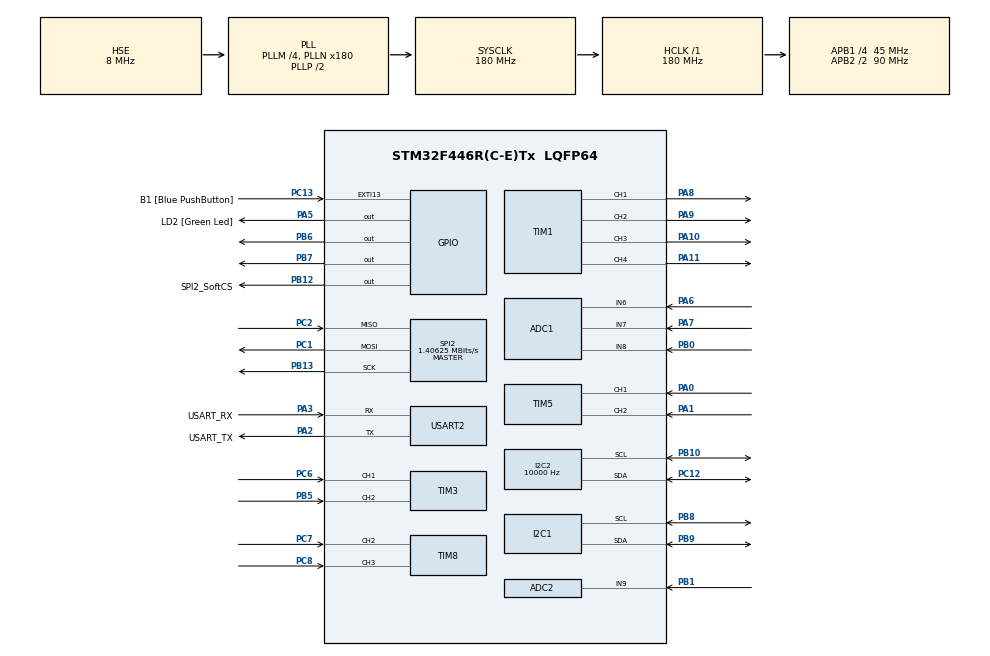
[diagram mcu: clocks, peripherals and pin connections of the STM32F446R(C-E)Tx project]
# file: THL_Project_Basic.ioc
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ADC1.Channel-0\#ChannelRegularConversion=ADC_CHANNEL_6
ADC1.Channel-1\#ChannelRegularConversion=ADC_CHANNEL_7
ADC1.Channel-2\#ChannelRegularConversion=ADC_CHANNEL_8
ADC1.Channel-3\#ChannelRegularConversion=ADC_CHANNEL_TEMPSENSOR
ADC1.ContinuousConvMode=ENABLE
ADC1.DMAContinuousRequests=ENABLE
ADC1.ExternalTrigConv=ADC_SOFTWARE_START
ADC1.InjNumberOfConversion=0
ADC1.NbrOfConversion=4
ADC1.NbrOfConversionFlag=1
ADC1.Rank-0\#ChannelRegularConversion=1
ADC1.Rank-1\#ChannelRegularConversion=2
ADC1.Rank-2\#ChannelRegularConversion=3
ADC1.Rank-3\#ChannelRegularConversion=4
ADC1.SamplingTime-0\#ChannelRegularConversion=ADC_SAMPLETIME_56CYCLES
ADC1.SamplingTime-1\#ChannelRegularConversion=ADC_SAMPLETIME_56CYCLES
ADC1.SamplingTime-2\#ChannelRegularConversion=ADC_SAMPLETIME_56CYCLES
ADC1.SamplingTime-3\#ChannelRegularConversion=ADC_SAMPLETIME_480CYCLES
ADC1.ScanConvMode=ENABLE
ADC1.master=1
ADC2.Channel-15\#ChannelRegularConversion=ADC_CHANNEL_9
ADC2.ContinuousConvMode=DISABLE
ADC2.NbrOfConversion=1
ADC2.NbrOfConversionFlag=1
ADC2.Rank-15\#ChannelRegularConversion=1
ADC2.SamplingTime-15\#ChannelRegularConversion=ADC_SAMPLETIME_480CYCLES
Dma.ADC1.4.Direction=DMA_PERIPH_TO_MEMORY
Dma.ADC1.4.FIFOMode=DMA_FIFOMODE_DISABLE
Dma.ADC1.4.Instance=DMA2_Stream0
Dma.ADC1.4.MemDataAlignment=DMA_MDATAALIGN_HALFWORD
Dma.ADC1.4.MemInc=DMA_MINC_ENABLE
Dma.ADC1.4.Mode=DMA_CIRCULAR
Dma.ADC1.4.PeriphDataAlignment=DMA_PDATAALIGN_HALFWORD
Dma.ADC1.4.PeriphInc=DMA_PINC_DISABLE
Dma.ADC1.4.Priority=DMA_PRIORITY_LOW
Dma.I2C1_RX.1.Direction=DMA_PERIPH_TO_MEMORY
Dma.I2C1_RX.1.FIFOMode=DMA_FIFOMODE_DISABLE
Dma.I2C1_RX.1.Instance=DMA1_Stream0
Dma.I2C1_RX.1.MemDataAlignment=DMA_MDATAALIGN_BYTE
Dma.I2C1_RX.1.MemInc=DMA_MINC_ENABLE
Dma.I2C1_RX.1.Mode=DMA_NORMAL
Dma.I2C1_RX.1.PeriphDataAlignment=DMA_PDATAALIGN_BYTE
Dma.I2C1_RX.1.PeriphInc=DMA_PINC_DISABLE
Dma.I2C1_RX.1.Priority=DMA_PRIORITY_VERY_HIGH
Dma.I2C1_TX.0.Direction=DMA_MEMORY_TO_PERIPH
Dma.I2C1_TX.0.FIFOMode=DMA_FIFOMODE_DISABLE
Dma.I2C1_TX.0.Instance=DMA1_Stream7
Dma.I2C1_TX.0.MemDataAlignment=DMA_MDATAALIGN_BYTE
Dma.I2C1_TX.0.MemInc=DMA_MINC_ENABLE
Dma.I2C1_TX.0.Mode=DMA_NORMAL
Dma.I2C1_TX.0.PeriphDataAlignment=DMA_PDATAALIGN_BYTE
Dma.I2C1_TX.0.PeriphInc=DMA_PINC_DISABLE
Dma.I2C1_TX.0.Priority=DMA_PRIORITY_VERY_HIGH
Dma.Request0=I2C1_TX
Dma.Request1=I2C1_RX
Dma.Request2=SPI2_RX
Dma.Request3=SPI2_TX
Dma.Request4=ADC1
Dma.SPI2_RX.2.Direction=DMA_PERIPH_TO_MEMORY
Dma.SPI2_RX.2.FIFOMode=DMA_FIFOMODE_DISABLE
Dma.SPI2_RX.2.Instance=DMA1_Stream3
Dma.SPI2_RX.2.MemDataAlignment=DMA_MDATAALIGN_BYTE
Dma.SPI2_RX.2.MemInc=DMA_MINC_ENABLE
Dma.SPI2_RX.2.Mode=DMA_NORMAL
Dma.SPI2_RX.2.PeriphDataAlignment=DMA_PDATAALIGN_BYTE
Dma.SPI2_RX.2.PeriphInc=DMA_PINC_DISABLE
Dma.SPI2_RX.2.Priority=DMA_PRIORITY_LOW
Dma.SPI2_TX.3.Direction=DMA_MEMORY_TO_PERIPH
Dma.SPI2_TX.3.FIFOMode=DMA_FIFOMODE_DISABLE
Dma.SPI2_TX.3.Instance=DMA1_Stream4
Dma.SPI2_TX.3.MemDataAlignment=DMA_MDATAALIGN_BYTE
Dma.SPI2_TX.3.MemInc=DMA_MINC_ENABLE
Dma.SPI2_TX.3.Mode=DMA_NORMAL
Dma.SPI2_TX.3.PeriphDataAlignment=DMA_PDATAALIGN_BYTE
Dma.SPI2_TX.3.PeriphInc=DMA_PINC_DISABLE
Dma.SPI2_TX.3.Priority=DMA_PRIORITY_LOW
I2C1.OwnAddress=6
I2C2.ClockSpeed=10000
I2C2.OwnAddress=3
Mcu.Family=STM32F4
Mcu.Name=STM32F446R(C-E)Tx
Mcu.Package=LQFP64
NVIC.ADC_IRQn=true\:0\:0\:false\:false\:true\:true
NVIC.DMA1_Stream0_IRQn=true\:0\:0\:false\:false\:true\:false
NVIC.DMA1_Stream3_IRQn=true\:0\:0\:false\:false\:true\:false
NVIC.DMA1_Stream4_IRQn=true\:0\:0\:false\:false\:true\:false
NVIC.DMA1_Stream7_IRQn=true\:0\:0\:false\:false\:true\:false
NVIC.DMA2_Stream0_IRQn=true\:0\:0\:false\:false\:true\:false
NVIC.I2C1_ER_IRQn=true\:0\:0\:false\:false\:true\:true
NVIC.I2C1_EV_IRQn=true\:0\:0\:false\:false\:true\:true
NVIC.PriorityGroup=NVIC_PRIORITYGROUP_4
NVIC.SPI2_IRQn=true\:0\:0\:false\:false\:true\:true
NVIC.TIM1_UP_TIM10_IRQn=true\:0\:0\:false\:false\:true\:true
NVIC.TIM3_IRQn=true\:0\:0\:false\:false\:true\:true
NVIC.TIM5_IRQn=true\:0\:0\:false\:false\:true\:true
NVIC.TIM7_IRQn=true\:0\:0\:false\:false\:true\:true
NVIC.TIM8_CC_IRQn=true\:0\:0\:false\:false\:true\:true
NVIC.TIM8_UP_TIM13_IRQn=true\:0\:0\:false\:false\:true\:true
PA0-WKUP.Signal=S_TIM5_CH1
PA1.Signal=S_TIM5_CH2
PA10.Signal=S_TIM1_CH3
PA11.Signal=S_TIM1_CH4
PA13.GPIO_Label=TMS
PA13.Mode=Serial_Wire
PA13.Signal=SYS_JTMS-SWDIO
PA14.GPIO_Label=TCK
PA14.Mode=Serial_Wire
PA14.Signal=SYS_JTCK-SWCLK
PA2.GPIO_Label=USART_TX
PA2.Mode=Asynchronous
PA2.Signal=USART2_TX
PA3.GPIO_Label=USART_RX
PA3.Mode=Asynchronous
PA3.Signal=USART2_RX
PA5.GPIO_Label=LD2 [Green Led]
PA5.Signal=GPIO_Output
PA6.Signal=ADCx_IN6
PA7.Signal=ADCx_IN7
PA8.Signal=S_TIM1_CH1
PA9.Signal=S_TIM1_CH2
PB0.Signal=ADCx_IN8
PB1.Signal=ADCx_IN9
PB10.GPIO_PuPdOD=GPIO_PULLUP
PB10.Mode=I2C
PB10.Signal=I2C2_SCL
PB12.GPIO_Label=SPI2_SoftCS
PB12.Signal=GPIO_Output
PB13.Mode=Full_Duplex_Master
PB13.Signal=SPI2_SCK
PB3.GPIO_Label=SWO
PB3.Signal=SYS_JTDO-SWO
PB5.Signal=S_TIM3_CH2
PB6.GPIO_Speed=GPIO_SPEED_FREQ_VERY_HIGH
PB6.Signal=GPIO_Output
PB7.GPIO_Speed=GPIO_SPEED_FREQ_VERY_HIGH
PB7.Signal=GPIO_Output
PB8.GPIO_Mode=GPIO_MODE_AF_OD
PB8.GPIO_PuPdOD=GPIO_NOPULL
PB8.Mode=I2C
PB8.Signal=I2C1_SCL
PB9.GPIO_PuPdOD=GPIO_NOPULL
PB9.Mode=I2C
PB9.Signal=I2C1_SDA
PC1.Mode=Full_Duplex_Master
PC1.Signal=SPI2_MOSI
PC12.Mode=I2C
PC12.Signal=I2C2_SDA
PC13.GPIO_Label=B1 [Blue PushButton]
PC13.GPIO_ModeDefaultEXTI=GPIO_MODE_IT_FALLING
PC13.Signal=GPXTI13
PC14-OSC32_IN.Mode=LSE-External-Oscillator
PC14-OSC32_IN.Signal=RCC_OSC32_IN
PC15-OSC32_OUT.Mode=LSE-External-Oscillator
PC15-OSC32_OUT.Signal=RCC_OSC32_OUT
PC2.Mode=Full_Duplex_Master
PC2.Signal=SPI2_MISO
PC6.Signal=S_TIM3_CH1
PC7.Signal=S_TIM8_CH2
PC8.Signal=S_TIM8_CH3
PH0-OSC_IN.Mode=HSE-External-Oscillator
PH0-OSC_IN.Signal=RCC_OSC_IN
PH1-OSC_OUT.Mode=HSE-External-Oscillator
PH1-OSC_OUT.Signal=RCC_OSC_OUT
ProjectManager.HeapSize=0x200
ProjectManager.StackSize=0x400
ProjectManager.TargetToolchain=TrueSTUDIO
RCC.48MHZClocksFreq_Value=84000000
RCC.AHBFreq_Value=180000000
RCC.APB1CLKDivider=RCC_HCLK_DIV4
RCC.APB1Freq_Value=45000000
RCC.APB1TimFreq_Value=90000000
RCC.APB2CLKDivider=RCC_HCLK_DIV2
RCC.APB2Freq_Value=90000000
RCC.APB2TimFreq_Value=180000000
RCC.CortexFreq_Value=180000000
RCC.FLatency-AdvancedSettings=FLASH_LATENCY_5
RCC.HCLKFreq_Value=180000000
RCC.HSE_VALUE=8000000
RCC.HSI_VALUE=16000000
RCC.PLLM=4
RCC.PLLN=180
RCC.PLLSourceVirtual=RCC_PLLSOURCE_HSE
RCC.SYSCLKFreq_VALUE=180000000
RCC.SYSCLKSource=RCC_SYSCLKSOURCE_PLLCLK
RCC.USBFreq_Value=180000000
RCC.VCOOutputFreq_Value=360000000
SH.ADCx_IN6.0=ADC1_IN6,IN6
SH.ADCx_IN7.0=ADC1_IN7,IN7
SH.ADCx_IN8.0=ADC1_IN8,IN8
SH.ADCx_IN9.0=ADC2_IN9,IN9
SH.S_TIM1_CH1.0=TIM1_CH1,PWM Generation1 CH1
SH.S_TIM1_CH2.0=TIM1_CH2,PWM Generation2 CH2
SH.S_TIM1_CH3.0=TIM1_CH3,PWM Generation3 CH3
SH.S_TIM1_CH4.0=TIM1_CH4,PWM Generation4 CH4
SH.S_TIM3_CH1.0=TIM3_CH1,Encoder_Interface
SH.S_TIM3_CH2.0=TIM3_CH2,Encoder_Interface
SH.S_TIM5_CH1.0=TIM5_CH1,Encoder_Interface
SH.S_TIM5_CH2.0=TIM5_CH2,Encoder_Interface
SH.S_TIM8_CH2.0=TIM8_CH2,Input_Capture2_from_TI2
SH.S_TIM8_CH3.0=TIM8_CH3,Input_Capture3_from_TI3
SPI2.BaudRatePrescaler=SPI_BAUDRATEPRESCALER_32
SPI2.CLKPhase=SPI_PHASE_2EDGE
SPI2.CLKPolarity=SPI_POLARITY_HIGH
SPI2.CalculateBaudRate=1.40625 MBits/s
SPI2.Direction=SPI_DIRECTION_2LINES
SPI2.Mode=SPI_MODE_MASTER
SPI2.TIMode=SPI_TIMODE_DISABLE
SPI2.VirtualType=VM_MASTER
TIM1.Channel-PWM\ Generation1\ CH1=TIM_CHANNEL_1
TIM1.Channel-PWM\ Generation2\ CH2=TIM_CHANNEL_2
TIM1.Channel-PWM\ Generation3\ CH3=TIM_CHANNEL_3
TIM1.Channel-PWM\ Generation4\ CH4=TIM_CHANNEL_4
TIM8.Channel-Input_Capture2_from_TI2=TIM_CHANNEL_2
TIM8.Channel-Input_Capture3_from_TI3=TIM_CHANNEL_3
USART2.VirtualMode=VM_ASYNC
VP_ADC1_TempSens_Input.Mode=IN-TempSens
VP_TIM10_VS_ClockSourceINT.Mode=Enable_Timer
VP_TIM7_VS_ClockSourceINT.Mode=Enable_Timer
board=NUCLEO-F446RE

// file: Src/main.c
/* USER CODE BEGIN Header */
/**
  ******************************************************************************
  * @file           : main.c
  * @brief          : Main program body
  ******************************************************************************
  ** This notice applies to any and all portions of this file
  * that are not between comment pairs USER CODE BEGIN and
  * USER CODE END. Other portions of this file, whether
  * inserted by the user or by software development tools
  * are owned by their respective copyright owners.
  *
  * COPYRIGHT(c) 2018 STMicroelectronics
  *
  * Redistribution and use in source and binary forms, with or without modification,
  * are permitted provided that the following conditions are met:
  *   1. Redistributions of source code must retain the above copyright notice,
  *      this list of conditions and the following disclaimer.
  *   2. Redistributions in binary form must reproduce the above copyright notice,
  *      this list of conditions and the following disclaimer in the documentation
  *      and/or other materials provided with the distribution.
  *   3. Neither the name of STMicroelectronics nor the names of its contributors
  *      may be used to endorse or promote products derived from this software
  *      without specific prior written permission.
  *
  * THIS SOFTWARE IS PROVIDED BY THE COPYRIGHT HOLDERS AND CONTRIBUTORS "AS IS"
  * AND ANY EXPRESS OR IMPLIED WARRANTIES, INCLUDING, BUT NOT LIMITED TO, THE
  * IMPLIED WARRANTIES OF MERCHANTABILITY AND FITNESS FOR A PARTICULAR PURPOSE ARE
  * DISCLAIMED. IN NO EVENT SHALL THE COPYRIGHT HOLDER OR CONTRIBUTORS BE LIABLE
  * FOR ANY DIRECT, INDIRECT, INCIDENTAL, SPECIAL, EXEMPLARY, OR CONSEQUENTIAL
  * DAMAGES (INCLUDING, BUT NOT LIMITED TO, PROCUREMENT OF SUBSTITUTE GOODS OR
  * SERVICES; LOSS OF USE, DATA, OR PROFITS; OR BUSINESS INTERRUPTION) HOWEVER
  * CAUSED AND ON ANY THEORY OF LIABILITY, WHETHER IN CONTRACT, STRICT LIABILITY,
  * OR TORT (INCLUDING NEGLIGENCE OR OTHERWISE) ARISING IN ANY WAY OUT OF THE USE
  * OF THIS SOFTWARE, EVEN IF ADVISED OF THE POSSIBILITY OF SUCH DAMAGE.
  *
  ******************************************************************************
  */
/* USER CODE END Header */

#include "main.h"

/* USER CODE BEGIN Includes */
#include "Prj_Main.h"
/* USER CODE END Includes */

ADC_HandleTypeDef hadc1;
ADC_HandleTypeDef hadc2;
DMA_HandleTypeDef hdma_adc1;

I2C_HandleTypeDef hi2c1;
I2C_HandleTypeDef hi2c2;
DMA_HandleTypeDef hdma_i2c1_tx;
DMA_HandleTypeDef hdma_i2c1_rx;

SPI_HandleTypeDef hspi2;
DMA_HandleTypeDef hdma_spi2_rx;
DMA_HandleTypeDef hdma_spi2_tx;

TIM_HandleTypeDef htim1;
TIM_HandleTypeDef htim3;
TIM_HandleTypeDef htim5;
TIM_HandleTypeDef htim7;
TIM_HandleTypeDef htim8;
TIM_HandleTypeDef htim10;

UART_HandleTypeDef huart2;

void SystemClock_Config(void);
static void MX_GPIO_Init(void);
static void MX_DMA_Init(void);
static void MX_USART2_UART_Init(void);
static void MX_TIM1_Init(void);
static void MX_I2C1_Init(void);
static void MX_I2C2_Init(void);
static void MX_SPI2_Init(void);
static void MX_ADC1_Init(void);
static void MX_TIM8_Init(void);
static void MX_TIM7_Init(void);
static void MX_TIM5_Init(void);
static void MX_TIM3_Init(void);
static void MX_TIM10_Init(void);
static void MX_ADC2_Init(void);

int main(void)
{

  /* MCU Configuration--------------------------------------------------------*/

  /* Reset of all peripherals, Initializes the Flash interface and the Systick. */
  HAL_Init();

  /* Configure the system clock */
  SystemClock_Config();

  /* Initialize all configured peripherals */
  MX_GPIO_Init();
  MX_DMA_Init();
  MX_USART2_UART_Init();
  MX_TIM1_Init();
  MX_I2C1_Init();
  MX_I2C2_Init();
  MX_SPI2_Init();
  MX_ADC1_Init();
  MX_TIM8_Init();
  MX_TIM7_Init();
  MX_TIM5_Init();
  MX_TIM3_Init();
  MX_TIM10_Init();
  MX_ADC2_Init();
  /* USER CODE BEGIN 2 */
  prj_main();
  /* USER CODE END 2 */

  /* Infinite loop */
  while (1)
  {

  }
}

void SystemClock_Config(void)
{
  RCC_OscInitTypeDef RCC_OscInitStruct = {0};
  RCC_ClkInitTypeDef RCC_ClkInitStruct = {0};

  /**Configure the main internal regulator output voltage
  */
  __HAL_RCC_PWR_CLK_ENABLE();
  __HAL_PWR_VOLTAGESCALING_CONFIG(PWR_REGULATOR_VOLTAGE_SCALE1);
  /**Initializes the CPU, AHB and APB busses clocks
  */
  RCC_OscInitStruct.OscillatorType = RCC_OSCILLATORTYPE_HSE;
  RCC_OscInitStruct.HSEState = RCC_HSE_ON;
  RCC_OscInitStruct.PLL.PLLState = RCC_PLL_ON;
  RCC_OscInitStruct.PLL.PLLSource = RCC_PLLSOURCE_HSE;
  RCC_OscInitStruct.PLL.PLLM = 4;
  RCC_OscInitStruct.PLL.PLLN = 180;
  RCC_OscInitStruct.PLL.PLLP = RCC_PLLP_DIV2;
  RCC_OscInitStruct.PLL.PLLQ = 2;
  RCC_OscInitStruct.PLL.PLLR = 2;
  if (HAL_RCC_OscConfig(&RCC_OscInitStruct) != HAL_OK)
  {
    Error_Handler();
  }
  /**Activate the Over-Drive mode
  */
  if (HAL_PWREx_EnableOverDrive() != HAL_OK)
  {
    Error_Handler();
  }
  /**Initializes the CPU, AHB and APB busses clocks
  */
  RCC_ClkInitStruct.ClockType = RCC_CLOCKTYPE_HCLK|RCC_CLOCKTYPE_SYSCLK
                              |RCC_CLOCKTYPE_PCLK1|RCC_CLOCKTYPE_PCLK2;
  RCC_ClkInitStruct.SYSCLKSource = RCC_SYSCLKSOURCE_PLLCLK;
  RCC_ClkInitStruct.AHBCLKDivider = RCC_SYSCLK_DIV1;
  RCC_ClkInitStruct.APB1CLKDivider = RCC_HCLK_DIV4;
  RCC_ClkInitStruct.APB2CLKDivider = RCC_HCLK_DIV2;

  if (HAL_RCC_ClockConfig(&RCC_ClkInitStruct, FLASH_LATENCY_5) != HAL_OK)
  {
    Error_Handler();
  }
}

static void MX_ADC1_Init(void)
{

  ADC_ChannelConfTypeDef sConfig = {0};

  /**Configure the global features of the ADC (Clock, Resolution, Data Alignment and number of conversion)
  */
  hadc1.Instance = ADC1;
  hadc1.Init.ClockPrescaler = ADC_CLOCK_SYNC_PCLK_DIV4;
  hadc1.Init.Resolution = ADC_RESOLUTION_12B;
  hadc1.Init.ScanConvMode = ENABLE;
  hadc1.Init.ContinuousConvMode = ENABLE;
  hadc1.Init.DiscontinuousConvMode = DISABLE;
  hadc1.Init.ExternalTrigConvEdge = ADC_EXTERNALTRIGCONVEDGE_NONE;
  hadc1.Init.ExternalTrigConv = ADC_SOFTWARE_START;
  hadc1.Init.DataAlign = ADC_DATAALIGN_RIGHT;
  hadc1.Init.NbrOfConversion = 4;
  hadc1.Init.DMAContinuousRequests = ENABLE;
  hadc1.Init.EOCSelection = ADC_EOC_SINGLE_CONV;
  if (HAL_ADC_Init(&hadc1) != HAL_OK)
  {
    Error_Handler();
  }
  /**Configure for the selected ADC regular channel its corresponding rank in the sequencer and its sample time.
  */
  sConfig.Channel = ADC_CHANNEL_6;
  sConfig.Rank = 1;
  sConfig.SamplingTime = ADC_SAMPLETIME_56CYCLES;
  if (HAL_ADC_ConfigChannel(&hadc1, &sConfig) != HAL_OK)
  {
    Error_Handler();
  }
  /**Configure for the selected ADC regular channel its corresponding rank in the sequencer and its sample time.
  */
  sConfig.Channel = ADC_CHANNEL_7;
  sConfig.Rank = 2;
  if (HAL_ADC_ConfigChannel(&hadc1, &sConfig) != HAL_OK)
  {
    Error_Handler();
  }
  /**Configure for the selected ADC regular channel its corresponding rank in the sequencer and its sample time.
  */
  sConfig.Channel = ADC_CHANNEL_8;
  sConfig.Rank = 3;
  if (HAL_ADC_ConfigChannel(&hadc1, &sConfig) != HAL_OK)
  {
    Error_Handler();
  }
  /**Configure for the selected ADC regular channel its corresponding rank in the sequencer and its sample time.
  */
  sConfig.Channel = ADC_CHANNEL_TEMPSENSOR;
  sConfig.Rank = 4;
  sConfig.SamplingTime = ADC_SAMPLETIME_480CYCLES;
  if (HAL_ADC_ConfigChannel(&hadc1, &sConfig) != HAL_OK)
  {
    Error_Handler();
  }

}

static void MX_ADC2_Init(void)
{

  ADC_ChannelConfTypeDef sConfig = {0};

  /**Configure the global features of the ADC (Clock, Resolution, Data Alignment and number of conversion)
  */
  hadc2.Instance = ADC2;
  hadc2.Init.ClockPrescaler = ADC_CLOCK_SYNC_PCLK_DIV4;
  hadc2.Init.Resolution = ADC_RESOLUTION_12B;
  hadc2.Init.ScanConvMode = DISABLE;
  hadc2.Init.ContinuousConvMode = DISABLE;
  hadc2.Init.DiscontinuousConvMode = DISABLE;
  hadc2.Init.ExternalTrigConvEdge = ADC_EXTERNALTRIGCONVEDGE_NONE;
  hadc2.Init.ExternalTrigConv = ADC_SOFTWARE_START;
  hadc2.Init.DataAlign = ADC_DATAALIGN_RIGHT;
  hadc2.Init.NbrOfConversion = 1;
  hadc2.Init.DMAContinuousRequests = DISABLE;
  hadc2.Init.EOCSelection = ADC_EOC_SINGLE_CONV;
  if (HAL_ADC_Init(&hadc2) != HAL_OK)
  {
    Error_Handler();
  }
  /**Configure for the selected ADC regular channel its corresponding rank in the sequencer and its sample time.
  */
  sConfig.Channel = ADC_CHANNEL_9;
  sConfig.Rank = 1;
  sConfig.SamplingTime = ADC_SAMPLETIME_480CYCLES;
  if (HAL_ADC_ConfigChannel(&hadc2, &sConfig) != HAL_OK)
  {
    Error_Handler();
  }

}

static void MX_I2C1_Init(void)
{

  hi2c1.Instance = I2C1;
  hi2c1.Init.ClockSpeed = 100000;
  hi2c1.Init.DutyCycle = I2C_DUTYCYCLE_2;
  hi2c1.Init.OwnAddress1 = 12;
  hi2c1.Init.AddressingMode = I2C_ADDRESSINGMODE_7BIT;
  hi2c1.Init.DualAddressMode = I2C_DUALADDRESS_DISABLE;
  hi2c1.Init.OwnAddress2 = 0;
  hi2c1.Init.GeneralCallMode = I2C_GENERALCALL_DISABLE;
  hi2c1.Init.NoStretchMode = I2C_NOSTRETCH_DISABLE;
  if (HAL_I2C_Init(&hi2c1) != HAL_OK)
  {
    Error_Handler();
  }

}

static void MX_I2C2_Init(void)
{

  hi2c2.Instance = I2C2;
  hi2c2.Init.ClockSpeed = 10000;
  hi2c2.Init.DutyCycle = I2C_DUTYCYCLE_2;
  hi2c2.Init.OwnAddress1 = 6;
  hi2c2.Init.AddressingMode = I2C_ADDRESSINGMODE_7BIT;
  hi2c2.Init.DualAddressMode = I2C_DUALADDRESS_DISABLE;
  hi2c2.Init.OwnAddress2 = 0;
  hi2c2.Init.GeneralCallMode = I2C_GENERALCALL_DISABLE;
  hi2c2.Init.NoStretchMode = I2C_NOSTRETCH_DISABLE;
  if (HAL_I2C_Init(&hi2c2) != HAL_OK)
  {
    Error_Handler();
  }

}

static void MX_SPI2_Init(void)
{

  /* SPI2 parameter configuration*/
  hspi2.Instance = SPI2;
  hspi2.Init.Mode = SPI_MODE_MASTER;
  hspi2.Init.Direction = SPI_DIRECTION_2LINES;
  hspi2.Init.DataSize = SPI_DATASIZE_8BIT;
  hspi2.Init.CLKPolarity = SPI_POLARITY_HIGH;
  hspi2.Init.CLKPhase = SPI_PHASE_2EDGE;
  hspi2.Init.NSS = SPI_NSS_SOFT;
  hspi2.Init.BaudRatePrescaler = SPI_BAUDRATEPRESCALER_32;
  hspi2.Init.FirstBit = SPI_FIRSTBIT_MSB;
  hspi2.Init.TIMode = SPI_TIMODE_DISABLE;
  hspi2.Init.CRCCalculation = SPI_CRCCALCULATION_DISABLE;
  hspi2.Init.CRCPolynomial = 10;
  if (HAL_SPI_Init(&hspi2) != HAL_OK)
  {
    Error_Handler();
  }

}

static void MX_TIM1_Init(void)
{

  TIM_MasterConfigTypeDef sMasterConfig = {0};
  TIM_OC_InitTypeDef sConfigOC = {0};
  TIM_BreakDeadTimeConfigTypeDef sBreakDeadTimeConfig = {0};

  htim1.Instance = TIM1;
  htim1.Init.Prescaler = 0;
  htim1.Init.CounterMode = TIM_COUNTERMODE_UP;
  htim1.Init.Period = 0;
  htim1.Init.ClockDivision = TIM_CLOCKDIVISION_DIV1;
  htim1.Init.RepetitionCounter = 0;
  if (HAL_TIM_PWM_Init(&htim1) != HAL_OK)
  {
    Error_Handler();
  }
  sMasterConfig.MasterOutputTrigger = TIM_TRGO_RESET;
  sMasterConfig.MasterSlaveMode = TIM_MASTERSLAVEMODE_DISABLE;
  if (HAL_TIMEx_MasterConfigSynchronization(&htim1, &sMasterConfig) != HAL_OK)
  {
    Error_Handler();
  }
  sConfigOC.OCMode = TIM_OCMODE_PWM1;
  sConfigOC.Pulse = 0;
  sConfigOC.OCPolarity = TIM_OCPOLARITY_HIGH;
  sConfigOC.OCNPolarity = TIM_OCNPOLARITY_HIGH;
  sConfigOC.OCFastMode = TIM_OCFAST_DISABLE;
  sConfigOC.OCIdleState = TIM_OCIDLESTATE_RESET;
  sConfigOC.OCNIdleState = TIM_OCNIDLESTATE_RESET;
  if (HAL_TIM_PWM_ConfigChannel(&htim1, &sConfigOC, TIM_CHANNEL_1) != HAL_OK)
  {
    Error_Handler();
  }
  if (HAL_TIM_PWM_ConfigChannel(&htim1, &sConfigOC, TIM_CHANNEL_2) != HAL_OK)
  {
    Error_Handler();
  }
  if (HAL_TIM_PWM_ConfigChannel(&htim1, &sConfigOC, TIM_CHANNEL_3) != HAL_OK)
  {
    Error_Handler();
  }
  if (HAL_TIM_PWM_ConfigChannel(&htim1, &sConfigOC, TIM_CHANNEL_4) != HAL_OK)
  {
    Error_Handler();
  }
  sBreakDeadTimeConfig.OffStateRunMode = TIM_OSSR_DISABLE;
  sBreakDeadTimeConfig.OffStateIDLEMode = TIM_OSSI_DISABLE;
  sBreakDeadTimeConfig.LockLevel = TIM_LOCKLEVEL_OFF;
  sBreakDeadTimeConfig.DeadTime = 0;
  sBreakDeadTimeConfig.BreakState = TIM_BREAK_DISABLE;
  sBreakDeadTimeConfig.BreakPolarity = TIM_BREAKPOLARITY_HIGH;
  sBreakDeadTimeConfig.AutomaticOutput = TIM_AUTOMATICOUTPUT_DISABLE;
  if (HAL_TIMEx_ConfigBreakDeadTime(&htim1, &sBreakDeadTimeConfig) != HAL_OK)
  {
    Error_Handler();
  }
  HAL_TIM_MspPostInit(&htim1);

}

static void MX_TIM3_Init(void)
{

  TIM_Encoder_InitTypeDef sConfig = {0};
  TIM_MasterConfigTypeDef sMasterConfig = {0};

  htim3.Instance = TIM3;
  htim3.Init.Prescaler = 0;
  htim3.Init.CounterMode = TIM_COUNTERMODE_UP;
  htim3.Init.Period = 0;
  htim3.Init.ClockDivision = TIM_CLOCKDIVISION_DIV1;
  sConfig.EncoderMode = TIM_ENCODERMODE_TI1;
  sConfig.IC1Polarity = TIM_ICPOLARITY_RISING;
  sConfig.IC1Selection = TIM_ICSELECTION_DIRECTTI;
  sConfig.IC1Prescaler = TIM_ICPSC_DIV1;
  sConfig.IC1Filter = 0;
  sConfig.IC2Polarity = TIM_ICPOLARITY_RISING;
  sConfig.IC2Selection = TIM_ICSELECTION_DIRECTTI;
  sConfig.IC2Prescaler = TIM_ICPSC_DIV1;
  sConfig.IC2Filter = 0;
  if (HAL_TIM_Encoder_Init(&htim3, &sConfig) != HAL_OK)
  {
    Error_Handler();
  }
  sMasterConfig.MasterOutputTrigger = TIM_TRGO_RESET;
  sMasterConfig.MasterSlaveMode = TIM_MASTERSLAVEMODE_DISABLE;
  if (HAL_TIMEx_MasterConfigSynchronization(&htim3, &sMasterConfig) != HAL_OK)
  {
    Error_Handler();
  }

}

static void MX_TIM5_Init(void)
{

  TIM_Encoder_InitTypeDef sConfig = {0};
  TIM_MasterConfigTypeDef sMasterConfig = {0};

  htim5.Instance = TIM5;
  htim5.Init.Prescaler = 0;
  htim5.Init.CounterMode = TIM_COUNTERMODE_UP;
  htim5.Init.Period = 0;
  htim5.Init.ClockDivision = TIM_CLOCKDIVISION_DIV1;
  sConfig.EncoderMode = TIM_ENCODERMODE_TI1;
  sConfig.IC1Polarity = TIM_ICPOLARITY_RISING;
  sConfig.IC1Selection = TIM_ICSELECTION_DIRECTTI;
  sConfig.IC1Prescaler = TIM_ICPSC_DIV1;
  sConfig.IC1Filter = 0;
  sConfig.IC2Polarity = TIM_ICPOLARITY_RISING;
  sConfig.IC2Selection = TIM_ICSELECTION_DIRECTTI;
  sConfig.IC2Prescaler = TIM_ICPSC_DIV1;
  sConfig.IC2Filter = 0;
  if (HAL_TIM_Encoder_Init(&htim5, &sConfig) != HAL_OK)
  {
    Error_Handler();
  }
  sMasterConfig.MasterOutputTrigger = TIM_TRGO_RESET;
  sMasterConfig.MasterSlaveMode = TIM_MASTERSLAVEMODE_DISABLE;
  if (HAL_TIMEx_MasterConfigSynchronization(&htim5, &sMasterConfig) != HAL_OK)
  {
    Error_Handler();
  }

}

static void MX_TIM7_Init(void)
{

  TIM_MasterConfigTypeDef sMasterConfig = {0};

  htim7.Instance = TIM7;
  htim7.Init.Prescaler = 0;
  htim7.Init.CounterMode = TIM_COUNTERMODE_UP;
  htim7.Init.Period = 0;
  if (HAL_TIM_Base_Init(&htim7) != HAL_OK)
  {
    Error_Handler();
  }
  sMasterConfig.MasterOutputTrigger = TIM_TRGO_RESET;
  sMasterConfig.MasterSlaveMode = TIM_MASTERSLAVEMODE_DISABLE;
  if (HAL_TIMEx_MasterConfigSynchronization(&htim7, &sMasterConfig) != HAL_OK)
  {
    Error_Handler();
  }

}

static void MX_TIM8_Init(void)
{

  TIM_MasterConfigTypeDef sMasterConfig = {0};
  TIM_IC_InitTypeDef sConfigIC = {0};

  htim8.Instance = TIM8;
  htim8.Init.Prescaler = 0;
  htim8.Init.CounterMode = TIM_COUNTERMODE_UP;
  htim8.Init.Period = 0;
  htim8.Init.ClockDivision = TIM_CLOCKDIVISION_DIV1;
  htim8.Init.RepetitionCounter = 0;
  if (HAL_TIM_IC_Init(&htim8) != HAL_OK)
  {
    Error_Handler();
  }
  sMasterConfig.MasterOutputTrigger = TIM_TRGO_RESET;
  sMasterConfig.MasterSlaveMode = TIM_MASTERSLAVEMODE_DISABLE;
  if (HAL_TIMEx_MasterConfigSynchronization(&htim8, &sMasterConfig) != HAL_OK)
  {
    Error_Handler();
  }
  sConfigIC.ICPolarity = TIM_INPUTCHANNELPOLARITY_RISING;
  sConfigIC.ICSelection = TIM_ICSELECTION_DIRECTTI;
  sConfigIC.ICPrescaler = TIM_ICPSC_DIV1;
  sConfigIC.ICFilter = 0;
  if (HAL_TIM_IC_ConfigChannel(&htim8, &sConfigIC, TIM_CHANNEL_2) != HAL_OK)
  {
    Error_Handler();
  }
  if (HAL_TIM_IC_ConfigChannel(&htim8, &sConfigIC, TIM_CHANNEL_3) != HAL_OK)
  {
    Error_Handler();
  }

}

static void MX_TIM10_Init(void)
{

  htim10.Instance = TIM10;
  htim10.Init.Prescaler = 0;
  htim10.Init.CounterMode = TIM_COUNTERMODE_UP;
  htim10.Init.Period = 0;
  htim10.Init.ClockDivision = TIM_CLOCKDIVISION_DIV1;
  if (HAL_TIM_Base_Init(&htim10) != HAL_OK)
  {
    Error_Handler();
  }

}

static void MX_USART2_UART_Init(void)
{

  huart2.Instance = USART2;
  huart2.Init.BaudRate = 115200;
  huart2.Init.WordLength = UART_WORDLENGTH_8B;
  huart2.Init.StopBits = UART_STOPBITS_1;
  huart2.Init.Parity = UART_PARITY_NONE;
  huart2.Init.Mode = UART_MODE_TX_RX;
  huart2.Init.HwFlowCtl = UART_HWCONTROL_NONE;
  huart2.Init.OverSampling = UART_OVERSAMPLING_16;
  if (HAL_UART_Init(&huart2) != HAL_OK)
  {
    Error_Handler();
  }

}

static void MX_DMA_Init(void)
{
  /* DMA controller clock enable */
  __HAL_RCC_DMA1_CLK_ENABLE();
  __HAL_RCC_DMA2_CLK_ENABLE();

  /* DMA interrupt init */
  /* DMA1_Stream0_IRQn interrupt configuration */
  HAL_NVIC_SetPriority(DMA1_Stream0_IRQn, 0, 0);
  HAL_NVIC_EnableIRQ(DMA1_Stream0_IRQn);
  /* DMA1_Stream3_IRQn interrupt configuration */
  HAL_NVIC_SetPriority(DMA1_Stream3_IRQn, 0, 0);
  HAL_NVIC_EnableIRQ(DMA1_Stream3_IRQn);
  /* DMA1_Stream4_IRQn interrupt configuration */
  HAL_NVIC_SetPriority(DMA1_Stream4_IRQn, 0, 0);
  HAL_NVIC_EnableIRQ(DMA1_Stream4_IRQn);
  /* DMA1_Stream7_IRQn interrupt configuration */
  HAL_NVIC_SetPriority(DMA1_Stream7_IRQn, 0, 0);
  HAL_NVIC_EnableIRQ(DMA1_Stream7_IRQn);
  /* DMA2_Stream0_IRQn interrupt configuration */
  HAL_NVIC_SetPriority(DMA2_Stream0_IRQn, 0, 0);
  HAL_NVIC_EnableIRQ(DMA2_Stream0_IRQn);

}

static void MX_GPIO_Init(void)
{
  GPIO_InitTypeDef GPIO_InitStruct = {0};

  /* GPIO Ports Clock Enable */
  __HAL_RCC_GPIOC_CLK_ENABLE();
  __HAL_RCC_GPIOH_CLK_ENABLE();
  __HAL_RCC_GPIOA_CLK_ENABLE();
  __HAL_RCC_GPIOB_CLK_ENABLE();

  /*Configure GPIO pin Output Level */
  HAL_GPIO_WritePin(LD2_GPIO_Port, LD2_Pin, GPIO_PIN_RESET);

  /*Configure GPIO pin Output Level */
  HAL_GPIO_WritePin(GPIOB, SPI2_SoftCS_Pin|GPIO_PIN_6|GPIO_PIN_7, GPIO_PIN_RESET);

  /*Configure GPIO pin : B1_Pin */
  GPIO_InitStruct.Pin = B1_Pin;
  GPIO_InitStruct.Mode = GPIO_MODE_IT_FALLING;
  GPIO_InitStruct.Pull = GPIO_NOPULL;
  HAL_GPIO_Init(B1_GPIO_Port, &GPIO_InitStruct);

  /*Configure GPIO pin : LD2_Pin */
  GPIO_InitStruct.Pin = LD2_Pin;
  GPIO_InitStruct.Mode = GPIO_MODE_OUTPUT_PP;
  GPIO_InitStruct.Pull = GPIO_NOPULL;
  GPIO_InitStruct.Speed = GPIO_SPEED_FREQ_LOW;
  HAL_GPIO_Init(LD2_GPIO_Port, &GPIO_InitStruct);

  /*Configure GPIO pin : SPI2_SoftCS_Pin */
  GPIO_InitStruct.Pin = SPI2_SoftCS_Pin;
  GPIO_InitStruct.Mode = GPIO_MODE_OUTPUT_PP;
  GPIO_InitStruct.Pull = GPIO_NOPULL;
  GPIO_InitStruct.Speed = GPIO_SPEED_FREQ_LOW;
  HAL_GPIO_Init(SPI2_SoftCS_GPIO_Port, &GPIO_InitStruct);

  /*Configure GPIO pins : PB6 PB7 */
  GPIO_InitStruct.Pin = GPIO_PIN_6|GPIO_PIN_7;
  GPIO_InitStruct.Mode = GPIO_MODE_OUTPUT_PP;
  GPIO_InitStruct.Pull = GPIO_NOPULL;
  GPIO_InitStruct.Speed = GPIO_SPEED_FREQ_VERY_HIGH;
  HAL_GPIO_Init(GPIOB, &GPIO_InitStruct);

}

void Error_Handler(void)
{
}

/************************ (C) COPYRIGHT STMicroelectronics *****END OF FILE****/
